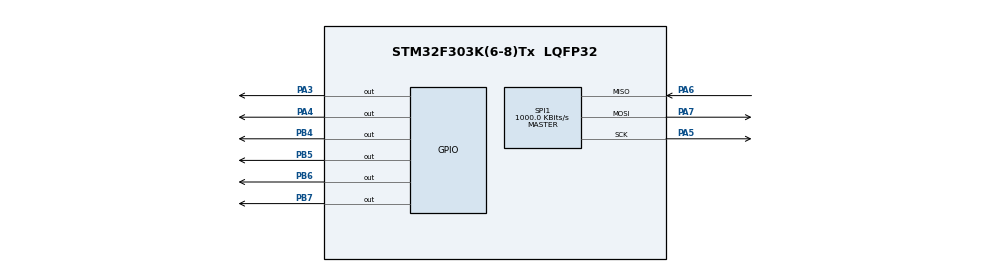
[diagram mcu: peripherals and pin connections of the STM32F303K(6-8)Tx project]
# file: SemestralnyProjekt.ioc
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Mcu.Family=STM32F3
Mcu.Name=STM32F303K(6-8)Tx
Mcu.Package=LQFP32
NVIC.PriorityGroup=NVIC_PRIORITYGROUP_4
PA3.Signal=GPIO_Output
PA4.Signal=GPIO_Output
PA5.Mode=Full_Duplex_Master
PA5.Signal=SPI1_SCK
PA6.Mode=Full_Duplex_Master
PA6.Signal=SPI1_MISO
PA7.Mode=Full_Duplex_Master
PA7.Signal=SPI1_MOSI
PB4.Signal=GPIO_Output
PB5.Signal=GPIO_Output
PB6.Signal=GPIO_Output
PB7.Signal=GPIO_Output
ProjectManager.HeapSize=0x200
ProjectManager.StackSize=0x400
ProjectManager.TargetToolchain=STM32CubeIDE
RCC.AHBFreq_Value=8000000
RCC.APB1Freq_Value=8000000
RCC.APB2Freq_Value=8000000
RCC.CortexFreq_Value=8000000
RCC.HSE_VALUE=8000000
RCC.HSI_VALUE=8000000
RCC.SYSCLKFreq_VALUE=8000000
SPI1.BaudRatePrescaler=SPI_BAUDRATEPRESCALER_8
SPI1.CalculateBaudRate=1000.0 KBits/s
SPI1.DataSize=SPI_DATASIZE_8BIT
SPI1.Direction=SPI_DIRECTION_2LINES
SPI1.Mode=SPI_MODE_MASTER
SPI1.VirtualType=VM_MASTER
board=custom

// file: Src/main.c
/* USER CODE BEGIN Header */
/**
  ******************************************************************************
  * @file           : main.c
  * @brief          : Main program body
  ******************************************************************************
  * @attention
  *
  * <h2><center>&copy; Copyright (c) 2019 STMicroelectronics.
  * All rights reserved.</center></h2>
  *
  * This software component is licensed by ST under BSD 3-Clause license,
  * the "License"; You may not use this file except in compliance with the
  * License. You may obtain a copy of the License at:
  *                        opensource.org/licenses/BSD-3-Clause
  *
  ******************************************************************************
  */
/* USER CODE END Header */

#include "main.h"
#include "spi.h"
#include "gpio.h"
#include "ili9163.h"
#include <stdio.h>

/* USER CODE BEGIN PV */
double temperature=0;
double pressure=0;
double humidity=0;
/* USER CODE END PV */

void SystemClock_Config(void);

int main(void)
{

  /* MCU Configuration--------------------------------------------------------*/

  /* Reset of all peripherals, Initializes the Flash interface and the Systick. */

  LL_APB2_GRP1_EnableClock(LL_APB2_GRP1_PERIPH_SYSCFG);
  LL_APB1_GRP1_EnableClock(LL_APB1_GRP1_PERIPH_PWR);

  NVIC_SetPriorityGrouping(NVIC_PRIORITYGROUP_4);

  /* System interrupt init*/

  /* Configure the system clock */
  SystemClock_Config();

  /* Initialize all configured peripherals */
  MX_GPIO_Init();
  MX_SPI1_Init();
/*
  initCD_Pin();
  initCS_Pin();
  initRES_Pin();

  LL_mDelay(50);
*/
  lcdInitialise(LCD_ORIENTATION3);
  lcdClearDisplay(decodeRgbValue(0, 0, 0));

  char stringToWrite[100];

  while (1)
  {
	  sprintf(stringToWrite,"Teplota    %.2f",temperature);
	  lcdPutS(stringToWrite, lcdTextX(2), lcdTextY(2), decodeRgbValue(255, 255, 255), decodeRgbValue(0, 0, 0));
	  sprintf(stringToWrite,"Vlhkost    %.2f",humidity);
	  lcdPutS(stringToWrite, lcdTextX(2), lcdTextY(6), decodeRgbValue(255, 255, 255), decodeRgbValue(0, 0, 0));
	  sprintf(stringToWrite,"Tlak       %.2f",pressure);
	  lcdPutS(stringToWrite, lcdTextX(2), lcdTextY(10), decodeRgbValue(255, 255, 255), decodeRgbValue(0, 0, 0));
  }
  /* USER CODE END 3 */
}

void SystemClock_Config(void)
{
  LL_FLASH_SetLatency(LL_FLASH_LATENCY_0);

  if(LL_FLASH_GetLatency() != LL_FLASH_LATENCY_0)
  {
  Error_Handler();
  }
  LL_RCC_HSI_Enable();

   /* Wait till HSI is ready */
  while(LL_RCC_HSI_IsReady() != 1)
  {

  }
  LL_RCC_HSI_SetCalibTrimming(16);
  LL_RCC_SetAHBPrescaler(LL_RCC_SYSCLK_DIV_1);
  LL_RCC_SetAPB1Prescaler(LL_RCC_APB1_DIV_1);
  LL_RCC_SetAPB2Prescaler(LL_RCC_APB1_DIV_1);
  LL_RCC_SetSysClkSource(LL_RCC_SYS_CLKSOURCE_HSI);

   /* Wait till System clock is ready */
  while(LL_RCC_GetSysClkSource() != LL_RCC_SYS_CLKSOURCE_STATUS_HSI)
  {

  }
  LL_Init1msTick(8000000);
  LL_SYSTICK_SetClkSource(LL_SYSTICK_CLKSOURCE_HCLK);
  LL_SetSystemCoreClock(8000000);
}

void Error_Handler(void)
{
}

/************************ (C) COPYRIGHT STMicroelectronics *****END OF FILE****/
